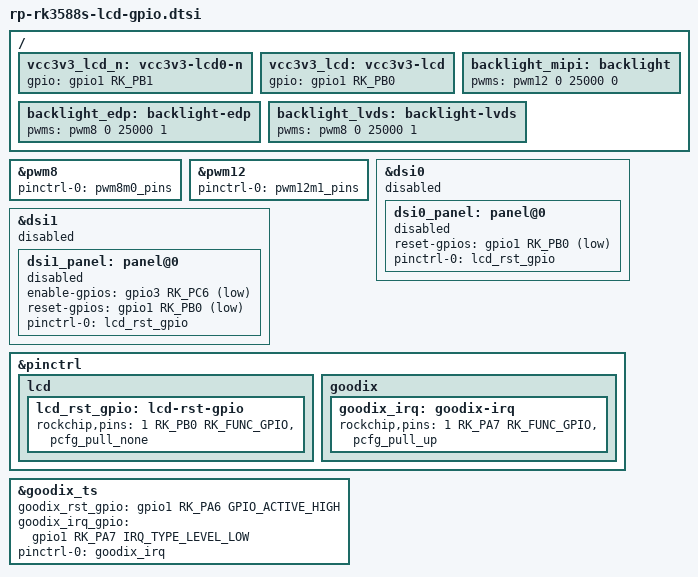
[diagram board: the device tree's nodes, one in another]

/ {
    vcc3v3_lcd_n: vcc3v3-lcd0-n {
    gpio = <&gpio1 RK_PB1 GPIO_ACTIVE_HIGH>;
  };

    vcc3v3_lcd: vcc3v3-lcd {
    gpio = <&gpio1 RK_PB0 GPIO_ACTIVE_HIGH>;
  };

    backlight_mipi: backlight {
    pwms = <&pwm12 0 25000 0>;
  };

    backlight_edp: backlight-edp {
    pwms = <&pwm8 0 25000 1>;
  };
  
    backlight_lvds: backlight-lvds {
    pwms = <&pwm8 0 25000 1>;
  };
};


&pwm8 {
    status = "okay";
    pinctrl-0 = <&pwm8m0_pins>;
};

&pwm12 {
    pinctrl-0 = <&pwm12m1_pins>;
    status = "okay";
};


&dsi0 {
    status = "disabled";
    dsi0_panel: panel@0 {
    status = "disabled";
    reset-gpios = <&gpio1 RK_PB0 GPIO_ACTIVE_LOW>;
    pinctrl-names = "default";
    pinctrl-0 = <&lcd_rst_gpio>;
  };
};

&dsi1 {
    status = "disabled";
    dsi1_panel: panel@0 {
    status = "disabled";
    enable-gpios = <&gpio3 RK_PC6 GPIO_ACTIVE_LOW>;
	reset-gpios = <&gpio1 RK_PB0 GPIO_ACTIVE_LOW>;
    pinctrl-names = "default";
    pinctrl-0 = <&lcd_rst_gpio>;
  };
};

&pinctrl {                                                                                                               
 lcd {
   lcd_rst_gpio: lcd-rst-gpio {
     rockchip,pins = <1 RK_PB0 RK_FUNC_GPIO &pcfg_pull_none>;
   };
 };

  goodix {
    goodix_irq: goodix-irq {
      rockchip,pins = <1 RK_PA7 RK_FUNC_GPIO &pcfg_pull_up>;
    };
  };
};

&goodix_ts {
        goodix_rst_gpio = <&gpio1 RK_PA6 GPIO_ACTIVE_HIGH>;
        goodix_irq_gpio = <&gpio1 RK_PA7 IRQ_TYPE_LEVEL_LOW>;
    pinctrl-names = "default";
    pinctrl-0 = <&goodix_irq>;
};
